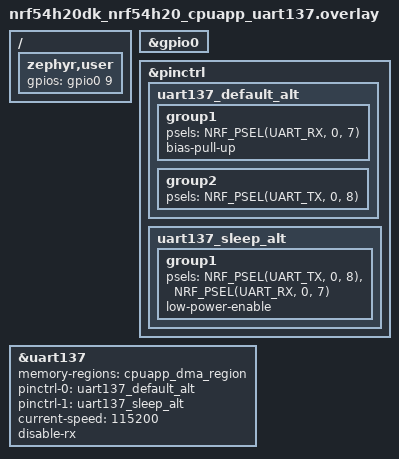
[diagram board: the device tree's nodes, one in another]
/*
 * Test requires wire connection between:
 *  - uart137 TX at P0.08 <-> GPIO input at P0.09
 */

/ {
	zephyr,user {
		gpios = <&gpio0 9 GPIO_ACTIVE_HIGH>;
	};
};

&gpio0 {
	status = "okay";
};

&pinctrl {
	uart137_default_alt: uart137_default_alt {
		group1 {
			psels = <NRF_PSEL(UART_RX, 0, 7)>;
			bias-pull-up;
		};
		group2 {
			psels = <NRF_PSEL(UART_TX, 0, 8)>;
		};
	};

	uart137_sleep_alt: uart137_sleep_alt {
		group1 {
			psels = <NRF_PSEL(UART_TX, 0, 8)>,
				<NRF_PSEL(UART_RX, 0, 7)>;
			low-power-enable;
		};
	};
};

dut: &uart137 {
	status = "okay";
	memory-regions = <&cpuapp_dma_region>;
	pinctrl-0 = <&uart137_default_alt>;
	pinctrl-1 = <&uart137_sleep_alt>;
	pinctrl-names = "default", "sleep";
	current-speed = <115200>;
	disable-rx;
};
